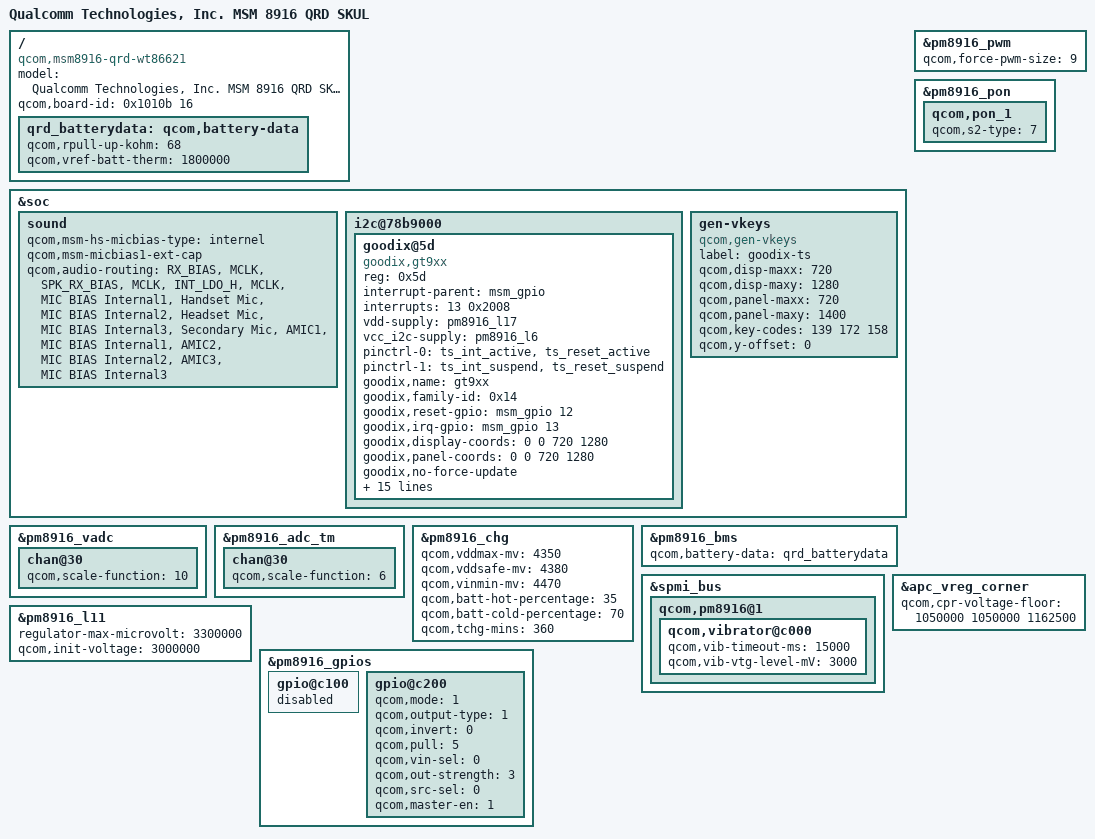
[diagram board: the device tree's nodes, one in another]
/* Copyright (c) 2014, The Linux Foundation. All rights reserved.
 *
 * This program is free software; you can redistribute it and/or modify
 * it under the terms of the GNU General Public License version 2 and
 * only version 2 as published by the Free Software Foundation.
 *
 * This program is distributed in the hope that it will be useful,
 * but WITHOUT ANY WARRANTY; without even the implied warranty of
 * MERCHANTABILITY or FITNESS FOR A PARTICULAR PURPOSE.  See the
 * GNU General Public License for more details.
 */

/dts-v1/;

#include "msm8916-qrd.dtsi"
#include "msm8916-memory.dtsi"
#include "wt86621/msm8916-wt86621.dtsi"

/ {
	model = "Qualcomm Technologies, Inc. MSM 8916 QRD SKUL";
	compatible = "qcom,msm8916-qrd-wt86621", "qcom,msm8916-qrd", "qcom,msm8916", "qcom,qrd";
	qcom,board-id = <0x1010b 16>;
};

&soc {
	sound {
		qcom,msm-hs-micbias-type = "internel";
		qcom,msm-micbias1-ext-cap;
		qcom,audio-routing =
			"RX_BIAS", "MCLK", 
			"SPK_RX_BIAS", "MCLK", 
			"INT_LDO_H", "MCLK", 
			"MIC BIAS Internal1", "Handset Mic", 
			"MIC BIAS Internal2", "Headset Mic", 
			"MIC BIAS Internal3", "Secondary Mic", 
			"AMIC1", "MIC BIAS Internal1", 
			"AMIC2", "MIC BIAS Internal2", 
			"AMIC3", "MIC BIAS Internal3";
	};

	i2c@78b9000 { /* BLSP1 QUP5 */ 
		goodix@5d {
			compatible = "goodix,gt9xx";
			reg = <0x5d>;
			interrupt-parent = <&msm_gpio>;
			interrupts = <13 0x2008>;
			vdd-supply = <&pm8916_l17>;
			vcc_i2c-supply = <&pm8916_l6>;
			pinctrl-names = "pmx_ts_active","pmx_ts_suspend";
			pinctrl-0 = <&ts_int_active &ts_reset_active>;
			pinctrl-1 = <&ts_int_suspend &ts_reset_suspend>;
			goodix,name = "gt9xx";
			goodix,family-id = <0x14>;
			goodix,reset-gpio = <&msm_gpio 12 0x0>;
			goodix,irq-gpio = <&msm_gpio 13 0x2008>;
			goodix,display-coords = <0 0 720 1280>;
			goodix,panel-coords = <0 0 720 1280>;
			goodix,no-force-update;
			goodix,i2c-pull-up;
			goodix,group-id = <1>;
			goodix,fw-upgrade-id1 = <0x11>;
			goodix,fw-upgrade-id2 = <0x11>;
			goodix,fw-delay-readid-ms = <10>;
			goodix,fw-delay-era-flsh-ms = <2000>;
			goodix,fw-auto-cal;
			// goodix,ignore-id-check;
			goodix,cfg-group0 = [48 d0 02 ec 04 05 34 61 01 c8 23 15 5f 46 0a 02 00 00 ff 6f 10 11 80 14 16 20 14 8a 2b 0b 37 39 d3 07 40 08 00 02 33 11 0a 00 00 00 14 1e 23 32 00 00 2a 1e 5a 94 c5 02 00 00 00 04 c6 21 00 a3 29 00 85 34 00 6f 41 00 5e 51 00 5e 10 30 50 00 f0 45 35 aa aa 27 00 00 00 00 00 00 00 00 00 00 00 00 00 00 00 00 00 00 00 00 00 19 00 00 50 00 02 04 06 08 0a 0c 0e 10 12 14 16 ff ff ff 1f ff 00 00 00 00 00 00 00 00 00 00 00 00 00 00 0f 04 0a 08 06 0c 02 10 12 00 26 18 1d 22 24 20 21 1e 1f 1c 16 ff ff ff ff ff 00 00 00 f1 ff ff ff ff ff ff ff ff ff ff ff ff e1 01];
			goodix,cfg-group1;
			goodix,cfg-group2 = [44 d0 02 f6 04 05 34 61 01 c8 23 15 5a 3c 03 02 00 00 ff 6f 10 00 80 14 16 21 14 8b 2a 0b 3c 3e d3 07 40 08 00 02 33 11 0a 00 00 00 19 23 1c 32 00 00 2a 1e 5a 94 c5 02 00 00 00 04 d4 21 00 af 29 00 8f 34 00 78 41 00 65 51 00 65 10 30 50 00 f0 40 30 fc dd 27 00 00 00 00 00 00 00 00 00 00 00 00 00 00 00 00 00 00 00 00 00 19 00 00 50 00 02 04 06 08 0a 0c 0e 10 12 14 16 ff ff ff 1f ff 00 00 00 00 00 00 00 00 00 00 00 00 00 00 24 16 22 18 21 1c 20 1d 1e 1f 10 06 00 0f 13 0c 12 0a 02 08 04 ff ff ff ff ff 00 00 00 f2 ff ff ff ff ff ff ff ff 3f ff ff ff 10 01];
			goodix,cfg-group3;
			goodix,cfg-group4;
			goodix,cfg-group5;
	    };
	};

	gen-vkeys {
		compatible = "qcom,gen-vkeys";
		label = "goodix-ts";
		qcom,disp-maxx = <720>;
		qcom,disp-maxy = <1280>;
		qcom,panel-maxx = <720>;
		qcom,panel-maxy = <1400>;
		qcom,key-codes = <139 172 158>;
		qcom,y-offset = <0>;
	};
};


&pm8916_vadc {
	chan@30 {
		qcom,scale-function = <10>;
	};
};

&pm8916_adc_tm {
	chan@30 {
		qcom,scale-function = <6>;
	};
};

&pm8916_chg {
	qcom,vddmax-mv = <4350>;
	qcom,vddsafe-mv = <4380>;
	qcom,vinmin-mv = <4470>;
	qcom,batt-hot-percentage = <35>;
	qcom,batt-cold-percentage = <70>;
	qcom,tchg-mins = <360>;
	status = "okay";
};

/ {
	qrd_batterydata: qcom,battery-data {
		qcom,rpull-up-kohm = <68>;
		qcom,vref-batt-therm = <1800000>;

		#include "batterydata-qrd-skuh-4v35-2000mah.dtsi"
		#include "batterydata-wingtech-4v35-3000mah.dtsi"
	};
};

&pm8916_bms {
	status = "ok";
	qcom,battery-data = <&qrd_batterydata>;
};

&pm8916_pwm {
	qcom,force-pwm-size = <9>;
};

&spmi_bus {
	qcom,pm8916@1 {
		qcom,vibrator@c000 {
			status = "okay";
			qcom,vib-timeout-ms = <15000>;
			qcom,vib-vtg-level-mV = <3000>;
		};
	};
};

&pm8916_l11 {
	regulator-max-microvolt = <3300000>;
	qcom,init-voltage = <3000000>;
};

&pm8916_pon {
	qcom,pon_1 {
		qcom,s2-type = <7>;
	};
};

&pm8916_gpios {
	gpio@c100 { /* GPIO 2 */
		/* NFC_CLK_REQ */
		status = "disabled";
	};

	gpio@c200 { /* GPIO 3 */
		/* Battery ID detect pin */
		qcom,mode = <1>;
		qcom,output-type = <1>;
		qcom,invert = <0>;
		qcom,pull = <5>;
		qcom,vin-sel = <0>;
		qcom,out-strength = <3>;
		qcom,src-sel = <0>;
		qcom,master-en = <1>;
		status = "ok";
	};
};

&apc_vreg_corner {
	qcom,cpr-voltage-floor = <1050000 1050000 1162500>;
};
